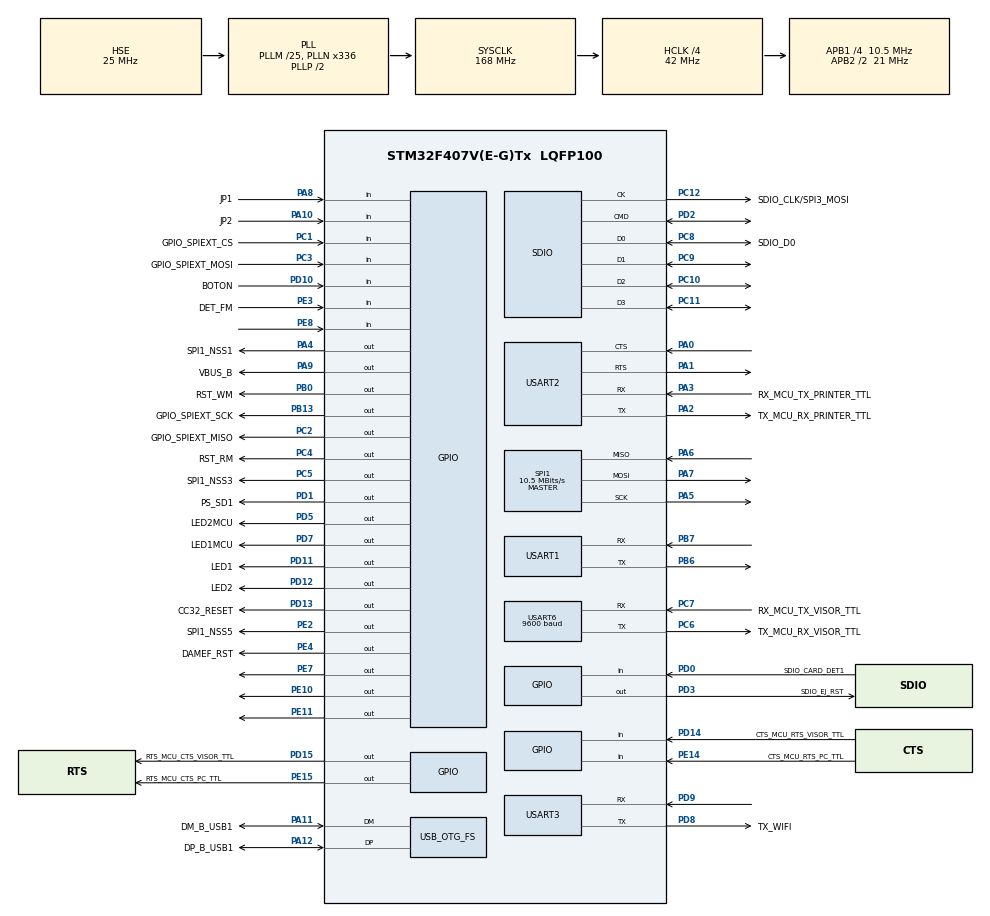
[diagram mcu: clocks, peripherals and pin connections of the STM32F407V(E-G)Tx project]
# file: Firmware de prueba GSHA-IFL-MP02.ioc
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Dma.Request0=SDIO_RX
Dma.Request1=SDIO_TX
Dma.SDIO_RX.0.Direction=DMA_PERIPH_TO_MEMORY
Dma.SDIO_RX.0.FIFOMode=DMA_FIFOMODE_ENABLE
Dma.SDIO_RX.0.FIFOThreshold=DMA_FIFO_THRESHOLD_FULL
Dma.SDIO_RX.0.Instance=DMA2_Stream3
Dma.SDIO_RX.0.MemBurst=DMA_MBURST_INC4
Dma.SDIO_RX.0.MemDataAlignment=DMA_MDATAALIGN_WORD
Dma.SDIO_RX.0.MemInc=DMA_MINC_ENABLE
Dma.SDIO_RX.0.Mode=DMA_PFCTRL
Dma.SDIO_RX.0.PeriphBurst=DMA_PBURST_INC4
Dma.SDIO_RX.0.PeriphDataAlignment=DMA_PDATAALIGN_WORD
Dma.SDIO_RX.0.PeriphInc=DMA_PINC_DISABLE
Dma.SDIO_RX.0.Priority=DMA_PRIORITY_LOW
Dma.SDIO_TX.1.Direction=DMA_MEMORY_TO_PERIPH
Dma.SDIO_TX.1.FIFOMode=DMA_FIFOMODE_ENABLE
Dma.SDIO_TX.1.FIFOThreshold=DMA_FIFO_THRESHOLD_FULL
Dma.SDIO_TX.1.Instance=DMA2_Stream6
Dma.SDIO_TX.1.MemBurst=DMA_MBURST_INC4
Dma.SDIO_TX.1.MemDataAlignment=DMA_MDATAALIGN_WORD
Dma.SDIO_TX.1.MemInc=DMA_MINC_ENABLE
Dma.SDIO_TX.1.Mode=DMA_PFCTRL
Dma.SDIO_TX.1.PeriphBurst=DMA_PBURST_INC4
Dma.SDIO_TX.1.PeriphDataAlignment=DMA_PDATAALIGN_WORD
Dma.SDIO_TX.1.PeriphInc=DMA_PINC_DISABLE
Dma.SDIO_TX.1.Priority=DMA_PRIORITY_LOW
FATFS.BSP.number=1
FATFS._MAX_SS=4096
FATFS0.BSP.STBoard=false
FATFS0.BSP.api=Unknown
FATFS0.BSP.i2caddr=0
FATFS0.BSP.instance=PD0
FATFS0.BSP.ip=GPIO
FATFS0.BSP.mode=Input
FATFS0.BSP.name=Detect_SDIO
FATFS0.BSP.solution=PD0
Mcu.Family=STM32F4
Mcu.Name=STM32F407V(E-G)Tx
Mcu.Package=LQFP100
NVIC.DMA2_Stream3_IRQn=true\:0\:0\:false\:false\:true\:true\:true
NVIC.DMA2_Stream6_IRQn=true\:0\:0\:false\:false\:true\:true\:true
NVIC.OTG_FS_IRQn=true\:0\:0\:false\:false\:true\:true\:true
NVIC.PriorityGroup=NVIC_PRIORITYGROUP_4
NVIC.SDIO_IRQn=true\:0\:0\:false\:false\:true\:true\:true
NVIC.USART2_IRQn=true\:0\:0\:false\:false\:true\:true\:true
NVIC.USART3_IRQn=true\:0\:0\:false\:false\:true\:true\:true
NVIC.USART6_IRQn=true\:0\:0\:false\:false\:true\:true\:true
PA0-WKUP.Mode=CTS_RTS
PA0-WKUP.Signal=USART2_CTS
PA1.Mode=CTS_RTS
PA1.Signal=USART2_RTS
PA10.GPIO_Label=JP2
PA10.Signal=GPIO_Input
PA11.GPIO_Label=DM_B_USB1
PA11.Mode=Device_Only
PA11.Signal=USB_OTG_FS_DM
PA12.GPIO_Label=DP_B_USB1
PA12.Mode=Device_Only
PA12.Signal=USB_OTG_FS_DP
PA13.Mode=JTAG_5_pins
PA13.Signal=SYS_JTMS-SWDIO
PA14.Mode=JTAG_5_pins
PA14.Signal=SYS_JTCK-SWCLK
PA15.Mode=JTAG_5_pins
PA15.Signal=SYS_JTDI
PA2.GPIO_Label=TX_MCU_RX_PRINTER_TTL
PA2.Mode=Asynchronous
PA2.Signal=USART2_TX
PA3.GPIO_Label=RX_MCU_TX_PRINTER_TTL
PA3.Mode=Asynchronous
PA3.Signal=USART2_RX
PA4.GPIO_Label=SPI1_NSS1
PA4.Signal=GPIO_Output
PA5.Mode=Full_Duplex_Master
PA5.Signal=SPI1_SCK
PA6.Mode=Full_Duplex_Master
PA6.Signal=SPI1_MISO
PA7.Mode=Full_Duplex_Master
PA7.Signal=SPI1_MOSI
PA8.GPIO_Label=JP1
PA8.Signal=GPIO_Input
PA9.GPIO_Label=VBUS_B
PA9.GPIO_Speed=GPIO_SPEED_FREQ_MEDIUM
PA9.PinState=GPIO_PIN_SET
PA9.Signal=GPIO_Output
PB0.GPIO_Label=RST_WM
PB0.Signal=GPIO_Output
PB13.GPIO_Label=GPIO_SPIEXT_SCK
PB13.Signal=GPIO_Output
PB3.Mode=JTAG_5_pins
PB3.Signal=SYS_JTDO-SWO
PB4.Mode=JTAG_5_pins
PB4.Signal=SYS_JTRST
PB6.Mode=Asynchronous
PB6.Signal=USART1_TX
PB7.Mode=Asynchronous
PB7.Signal=USART1_RX
PC1.GPIO_Label=GPIO_SPIEXT_CS
PC1.Signal=GPIO_Input
PC10.Mode=SD_4_bits_Wide_bus
PC10.Signal=SDIO_D2
PC11.Mode=SD_4_bits_Wide_bus
PC11.Signal=SDIO_D3
PC12.GPIO_Label=SDIO_CLK/SPI3_MOSI
PC12.GPIO_Mode=GPIO_MODE_AF_PP
PC12.GPIO_PuPd=GPIO_NOPULL
PC12.GPIO_Speed_High_Default=GPIO_SPEED_FREQ_VERY_HIGH
PC12.Mode=SD_4_bits_Wide_bus
PC12.Signal=SDIO_CK
PC14-OSC32_IN.Mode=LSE-External-Oscillator
PC14-OSC32_IN.Signal=RCC_OSC32_IN
PC15-OSC32_OUT.Mode=LSE-External-Oscillator
PC15-OSC32_OUT.Signal=RCC_OSC32_OUT
PC2.GPIO_Label=GPIO_SPIEXT_MISO
PC2.Signal=GPIO_Output
PC3.GPIO_Label=GPIO_SPIEXT_MOSI
PC3.Signal=GPIO_Input
PC4.GPIO_Label=RST_RM
PC4.GPIO_ModeDefaultOutputPP=GPIO_MODE_OUTPUT_PP
PC4.GPIO_PuPd=GPIO_NOPULL
PC4.GPIO_Speed=GPIO_SPEED_FREQ_VERY_HIGH
PC4.PinState=GPIO_PIN_SET
PC4.Signal=GPIO_Output
PC5.GPIO_Label=SPI1_NSS3
PC5.GPIO_ModeDefaultOutputPP=GPIO_MODE_OUTPUT_PP
PC5.GPIO_PuPd=GPIO_NOPULL
PC5.GPIO_Speed=GPIO_SPEED_FREQ_VERY_HIGH
PC5.PinState=GPIO_PIN_SET
PC5.Signal=GPIO_Output
PC6.GPIO_Label=TX_MCU_RX_VISOR_TTL
PC6.Mode=Asynchronous
PC6.Signal=USART6_TX
PC7.GPIO_Label=RX_MCU_TX_VISOR_TTL
PC7.Mode=Asynchronous
PC7.Signal=USART6_RX
PC8.GPIO_Label=SDIO_D0
PC8.GPIO_Mode=GPIO_MODE_AF_PP
PC8.GPIO_PuPd=GPIO_PULLUP
PC8.GPIO_Speed_High_Default=GPIO_SPEED_FREQ_VERY_HIGH
PC8.Mode=SD_4_bits_Wide_bus
PC8.Signal=SDIO_D0
PC9.Mode=SD_4_bits_Wide_bus
PC9.Signal=SDIO_D1
PD0.GPIO_Label=SDIO_CARD_DET1
PD0.Signal=GPIO_Input
PD1.GPIO_Label=PS_SD1
PD1.GPIO_Speed=GPIO_SPEED_FREQ_MEDIUM
PD1.Signal=GPIO_Output
PD10.GPIO_Label=BOTON
PD10.GPIO_PuPd=GPIO_PULLUP
PD10.Signal=GPIO_Input
PD11.GPIO_Label=LED1
PD11.GPIO_ModeDefaultOutputPP=GPIO_MODE_OUTPUT_PP
PD11.GPIO_PuPd=GPIO_NOPULL
PD11.GPIO_Speed=GPIO_SPEED_FREQ_HIGH
PD11.PinState=GPIO_PIN_RESET
PD11.Signal=GPIO_Output
PD12.GPIO_Label=LED2
PD12.GPIO_ModeDefaultOutputPP=GPIO_MODE_OUTPUT_PP
PD12.GPIO_PuPd=GPIO_NOPULL
PD12.GPIO_Speed=GPIO_SPEED_FREQ_HIGH
PD12.PinState=GPIO_PIN_RESET
PD12.Signal=GPIO_Output
PD13.GPIO_Label=CC32_RESET
PD13.Signal=GPIO_Output
PD14.GPIO_Label=CTS_MCU_RTS_VISOR_TTL
PD14.Signal=GPIO_Input
PD15.GPIO_Label=RTS_MCU_CTS_VISOR_TTL
PD15.Signal=GPIO_Output
PD2.GPIO_Mode=GPIO_MODE_AF_PP
PD2.GPIO_PuPd=GPIO_PULLUP
PD2.GPIO_Speed_High_Default=GPIO_SPEED_FREQ_VERY_HIGH
PD2.Mode=SD_4_bits_Wide_bus
PD2.Signal=SDIO_CMD
PD3.GPIO_Label=SDIO_EJ_RST
PD3.Signal=GPIO_Output
PD5.GPIO_Label=LED2MCU
PD5.Signal=GPIO_Output
PD7.GPIO_Label=LED1MCU
PD7.Signal=GPIO_Output
PD8.GPIO_Label=TX_WIFI
PD8.Mode=Asynchronous
PD8.Signal=USART3_TX
PD9.Mode=Asynchronous
PD9.Signal=USART3_RX
PE10.Signal=GPIO_Output
PE11.Signal=GPIO_Output
PE14.GPIO_Label=CTS_MCU_RTS_PC_TTL
PE14.Signal=GPIO_Input
PE15.GPIO_Label=RTS_MCU_CTS_PC_TTL
PE15.Signal=GPIO_Output
PE2.GPIO_Label=SPI1_NSS5
PE2.GPIO_Speed=GPIO_SPEED_FREQ_VERY_HIGH
PE2.PinState=GPIO_PIN_SET
PE2.Signal=GPIO_Output
PE3.GPIO_Label=DET_FM
PE3.Signal=GPIO_Input
PE4.GPIO_Label=DAMEF_RST
PE4.GPIO_Speed=GPIO_SPEED_FREQ_VERY_HIGH
PE4.PinState=GPIO_PIN_SET
PE4.Signal=GPIO_Output
PE7.Signal=GPIO_Output
PE8.Signal=GPIO_Input
PH0-OSC_IN.Mode=HSE-External-Oscillator
PH0-OSC_IN.Signal=RCC_OSC_IN
PH1-OSC_OUT.Mode=HSE-External-Oscillator
PH1-OSC_OUT.Signal=RCC_OSC_OUT
ProjectManager.HeapSize=0x2000
ProjectManager.StackSize=0x4000
ProjectManager.TargetToolchain=MDK-ARM V5
RCC.48MHZClocksFreq_Value=48000000
RCC.AHBCLKDivider=RCC_SYSCLK_DIV4
RCC.AHBFreq_Value=42000000
RCC.APB1CLKDivider=RCC_HCLK_DIV4
RCC.APB1Freq_Value=10500000
RCC.APB1TimFreq_Value=21000000
RCC.APB2CLKDivider=RCC_HCLK_DIV2
RCC.APB2Freq_Value=21000000
RCC.APB2TimFreq_Value=42000000
RCC.CortexFreq_Value=42000000
RCC.HCLKFreq_Value=42000000
RCC.HSE_VALUE=25000000
RCC.HSI_VALUE=16000000
RCC.PLLM=25
RCC.PLLN=336
RCC.PLLQ=7
RCC.RCC_RTC_Clock_Source=RCC_RTCCLKSOURCE_LSE
RCC.RCC_RTC_Clock_SourceVirtual=RCC_RTCCLKSOURCE_LSE
RCC.SYSCLKFreq_VALUE=168000000
RCC.SYSCLKSource=RCC_SYSCLKSOURCE_PLLCLK
RCC.VCOOutputFreq_Value=336000000
RTC.Alarm=RTC_ALARM_A
SDIO.ClockDiv=3
SDIO.WideMode=SDIO_BUS_WIDE_4B
SPI1.CalculateBaudRate=10.5 MBits/s
SPI1.Direction=SPI_DIRECTION_2LINES
SPI1.Mode=SPI_MODE_MASTER
SPI1.VirtualType=VM_MASTER
USART1.VirtualMode=VM_ASYNC
USART2.VirtualMode=VM_ASYNC
USART3.VirtualMode=VM_ASYNC
USART6.BaudRate=9600
USART6.VirtualMode=VM_ASYNC
USB_DEVICE.CLASS_NAME-CDC_FS=CDC
USB_DEVICE.CLASS_NAME_FS=CDC
USB_DEVICE.MANUFACTURER_STRING-CDC_FS=The Factory HKA
USB_DEVICE.PRODUCT_STRING_CDC_FS=Tarjeta de comunicaicon HKA
USB_DEVICE.USBD_HandleTypeDef-CDC_FS=hUsbDeviceFS
USB_DEVICE.VirtualMode-CDC_FS=Cdc
USB_DEVICE.VirtualModeFS=Cdc_FS
USB_OTG_FS.VirtualMode=Device_Only
VP_FATFS_VS_SDIO.Mode=SDIO
VP_RTC_VS_RTC_Activate.Mode=RTC_Enabled
VP_RTC_VS_RTC_Alarm_A_Intern.Mode=Alarm A
VP_RTC_VS_RTC_Calendar.Mode=RTC_Calendar
VP_USB_DEVICE_VS_USB_DEVICE_CDC_FS.Mode=CDC_FS
board=Firmware de prueba GSHA-IFL-MP02

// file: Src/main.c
/* USER CODE BEGIN Header */
/**
  ******************************************************************************
  * @file           : main.c
  * @brief          : Main program body
  ******************************************************************************
  * @attention
  *
  * <h2><center>&copy; Copyright (c) 2021 STMicroelectronics.
  * All rights reserved.</center></h2>
  *
  * This software component is licensed by ST under Ultimate Liberty license
  * SLA0044, the "License"; You may not use this file except in compliance with
  * the License. You may obtain a copy of the License at:
  *                             www.st.com/SLA0044
  *
  ******************************************************************************
  */
/* USER CODE END Header */
#include "main.h"
#include "fatfs.h"
#include "usb_device.h"

/* USER CODE BEGIN Includes */
//#include "UartRingbuffer.h"
//#include "file_handling.h"
#include "selftest.h"
/* USER CODE END Includes */

RTC_HandleTypeDef hrtc;

SD_HandleTypeDef hsd;
DMA_HandleTypeDef hdma_sdio_rx;
DMA_HandleTypeDef hdma_sdio_tx;

SPI_HandleTypeDef hspi1;

UART_HandleTypeDef huart1;
UART_HandleTypeDef huart2;
UART_HandleTypeDef huart3;
UART_HandleTypeDef huart6;

void SystemClock_Config(void);
static void MX_GPIO_Init(void);
static void MX_DMA_Init(void);
static void MX_RTC_Init(void);
static void MX_SDIO_SD_Init(void);
static void MX_USART1_UART_Init(void);
static void MX_USART2_UART_Init(void);
static void MX_USART6_UART_Init(void);
static void MX_USART3_UART_Init(void);
static void MX_SPI1_Init(void);

int main(void)
{

  /* MCU Configuration--------------------------------------------------------*/

  /* Reset of all peripherals, Initializes the Flash interface and the Systick. */
  HAL_Init();

  /* Configure the system clock */
  SystemClock_Config();

  /* Initialize all configured peripherals */
  MX_GPIO_Init();
  MX_DMA_Init();
  MX_RTC_Init();
  MX_SDIO_SD_Init();
  MX_USART1_UART_Init();
  MX_USART2_UART_Init();
  MX_USART6_UART_Init();
  MX_FATFS_Init();
  MX_USB_DEVICE_Init();
  MX_USART3_UART_Init();
  MX_SPI1_Init();
  /* USER CODE BEGIN 2 */
  int loop=3;
  /* USER CODE END 2 */

  /* Infinite loop */
  /* USER CODE BEGIN WHILE */
  while (1)
  {
		HAL_Delay(2000);
    //Mensaje inicial

		ALLISON_init();

		//Ejecucion del selftest del STM32

		selftest();

		while(loop){
		led_ok();
			loop--;
		}

    //Prueba del CC3220

		CC32_Selftest();

		//while(1){}

}	/* USER CODE END WHILE */

}
void SystemClock_Config(void)
{
  RCC_OscInitTypeDef RCC_OscInitStruct = {0};
  RCC_ClkInitTypeDef RCC_ClkInitStruct = {0};
  RCC_PeriphCLKInitTypeDef PeriphClkInitStruct = {0};

  /** Configure the main internal regulator output voltage
  */
  __HAL_RCC_PWR_CLK_ENABLE();
  __HAL_PWR_VOLTAGESCALING_CONFIG(PWR_REGULATOR_VOLTAGE_SCALE1);
  /** Initializes the RCC Oscillators according to the specified parameters
  * in the RCC_OscInitTypeDef structure.
  */
  RCC_OscInitStruct.OscillatorType = RCC_OSCILLATORTYPE_HSE|RCC_OSCILLATORTYPE_LSE;
  RCC_OscInitStruct.HSEState = RCC_HSE_ON;
  RCC_OscInitStruct.LSEState = RCC_LSE_ON;
  RCC_OscInitStruct.PLL.PLLState = RCC_PLL_ON;
  RCC_OscInitStruct.PLL.PLLSource = RCC_PLLSOURCE_HSE;
  RCC_OscInitStruct.PLL.PLLM = 25;
  RCC_OscInitStruct.PLL.PLLN = 336;
  RCC_OscInitStruct.PLL.PLLP = RCC_PLLP_DIV2;
  RCC_OscInitStruct.PLL.PLLQ = 7;
  if (HAL_RCC_OscConfig(&RCC_OscInitStruct) != HAL_OK)
  {
    Error_Handler();
  }
  /** Initializes the CPU, AHB and APB buses clocks
  */
  RCC_ClkInitStruct.ClockType = RCC_CLOCKTYPE_HCLK|RCC_CLOCKTYPE_SYSCLK
                              |RCC_CLOCKTYPE_PCLK1|RCC_CLOCKTYPE_PCLK2;
  RCC_ClkInitStruct.SYSCLKSource = RCC_SYSCLKSOURCE_PLLCLK;
  RCC_ClkInitStruct.AHBCLKDivider = RCC_SYSCLK_DIV4;
  RCC_ClkInitStruct.APB1CLKDivider = RCC_HCLK_DIV4;
  RCC_ClkInitStruct.APB2CLKDivider = RCC_HCLK_DIV2;

  if (HAL_RCC_ClockConfig(&RCC_ClkInitStruct, FLASH_LATENCY_1) != HAL_OK)
  {
    Error_Handler();
  }
  PeriphClkInitStruct.PeriphClockSelection = RCC_PERIPHCLK_RTC;
  PeriphClkInitStruct.RTCClockSelection = RCC_RTCCLKSOURCE_LSE;
  if (HAL_RCCEx_PeriphCLKConfig(&PeriphClkInitStruct) != HAL_OK)
  {
    Error_Handler();
  }
}

static void MX_RTC_Init(void)
{

  RTC_TimeTypeDef sTime = {0};
  RTC_DateTypeDef sDate = {0};
  RTC_AlarmTypeDef sAlarm = {0};

  /** Initialize RTC Only
  */
  hrtc.Instance = RTC;
  hrtc.Init.HourFormat = RTC_HOURFORMAT_24;
  hrtc.Init.AsynchPrediv = 127;
  hrtc.Init.SynchPrediv = 255;
  hrtc.Init.OutPut = RTC_OUTPUT_DISABLE;
  hrtc.Init.OutPutPolarity = RTC_OUTPUT_POLARITY_HIGH;
  hrtc.Init.OutPutType = RTC_OUTPUT_TYPE_OPENDRAIN;
  if (HAL_RTC_Init(&hrtc) != HAL_OK)
  {
    Error_Handler();
  }

  /** Initialize RTC and set the Time and Date
  */
  sTime.Hours = 0x0;
  sTime.Minutes = 0x0;
  sTime.Seconds = 0x0;
  sTime.DayLightSaving = RTC_DAYLIGHTSAVING_NONE;
  sTime.StoreOperation = RTC_STOREOPERATION_RESET;
  if (HAL_RTC_SetTime(&hrtc, &sTime, RTC_FORMAT_BCD) != HAL_OK)
  {
    Error_Handler();
  }
  sDate.WeekDay = RTC_WEEKDAY_MONDAY;
  sDate.Month = RTC_MONTH_JANUARY;
  sDate.Date = 0x1;
  sDate.Year = 0x0;

  if (HAL_RTC_SetDate(&hrtc, &sDate, RTC_FORMAT_BCD) != HAL_OK)
  {
    Error_Handler();
  }
  /** Enable the Alarm A
  */
  sAlarm.AlarmTime.Hours = 0x0;
  sAlarm.AlarmTime.Minutes = 0x0;
  sAlarm.AlarmTime.Seconds = 0x0;
  sAlarm.AlarmTime.SubSeconds = 0x0;
  sAlarm.AlarmTime.DayLightSaving = RTC_DAYLIGHTSAVING_NONE;
  sAlarm.AlarmTime.StoreOperation = RTC_STOREOPERATION_RESET;
  sAlarm.AlarmMask = RTC_ALARMMASK_NONE;
  sAlarm.AlarmSubSecondMask = RTC_ALARMSUBSECONDMASK_ALL;
  sAlarm.AlarmDateWeekDaySel = RTC_ALARMDATEWEEKDAYSEL_DATE;
  sAlarm.AlarmDateWeekDay = 0x1;
  sAlarm.Alarm = RTC_ALARM_A;
  if (HAL_RTC_SetAlarm(&hrtc, &sAlarm, RTC_FORMAT_BCD) != HAL_OK)
  {
    Error_Handler();
  }

}

static void MX_SDIO_SD_Init(void)
{

  hsd.Instance = SDIO;
  hsd.Init.ClockEdge = SDIO_CLOCK_EDGE_RISING;
  hsd.Init.ClockBypass = SDIO_CLOCK_BYPASS_DISABLE;
  hsd.Init.ClockPowerSave = SDIO_CLOCK_POWER_SAVE_DISABLE;
  hsd.Init.BusWide = SDIO_BUS_WIDE_1B;
  hsd.Init.HardwareFlowControl = SDIO_HARDWARE_FLOW_CONTROL_DISABLE;
  hsd.Init.ClockDiv = 3;

}

static void MX_SPI1_Init(void)
{

  /* SPI1 parameter configuration*/
  hspi1.Instance = SPI1;
  hspi1.Init.Mode = SPI_MODE_MASTER;
  hspi1.Init.Direction = SPI_DIRECTION_2LINES;
  hspi1.Init.DataSize = SPI_DATASIZE_8BIT;
  hspi1.Init.CLKPolarity = SPI_POLARITY_LOW;
  hspi1.Init.CLKPhase = SPI_PHASE_1EDGE;
  hspi1.Init.NSS = SPI_NSS_SOFT;
  hspi1.Init.BaudRatePrescaler = SPI_BAUDRATEPRESCALER_2;
  hspi1.Init.FirstBit = SPI_FIRSTBIT_MSB;
  hspi1.Init.TIMode = SPI_TIMODE_DISABLE;
  hspi1.Init.CRCCalculation = SPI_CRCCALCULATION_DISABLE;
  hspi1.Init.CRCPolynomial = 10;
  if (HAL_SPI_Init(&hspi1) != HAL_OK)
  {
    Error_Handler();
  }

}

static void MX_USART1_UART_Init(void)
{

  huart1.Instance = USART1;
  huart1.Init.BaudRate = 115200;
  huart1.Init.WordLength = UART_WORDLENGTH_8B;
  huart1.Init.StopBits = UART_STOPBITS_1;
  huart1.Init.Parity = UART_PARITY_NONE;
  huart1.Init.Mode = UART_MODE_TX_RX;
  huart1.Init.HwFlowCtl = UART_HWCONTROL_NONE;
  huart1.Init.OverSampling = UART_OVERSAMPLING_16;
  if (HAL_UART_Init(&huart1) != HAL_OK)
  {
    Error_Handler();
  }

}

static void MX_USART2_UART_Init(void)
{

  huart2.Instance = USART2;
  huart2.Init.BaudRate = 115200;
  huart2.Init.WordLength = UART_WORDLENGTH_8B;
  huart2.Init.StopBits = UART_STOPBITS_1;
  huart2.Init.Parity = UART_PARITY_NONE;
  huart2.Init.Mode = UART_MODE_TX_RX;
  huart2.Init.HwFlowCtl = UART_HWCONTROL_RTS_CTS;
  huart2.Init.OverSampling = UART_OVERSAMPLING_16;
  if (HAL_UART_Init(&huart2) != HAL_OK)
  {
    Error_Handler();
  }

}

static void MX_USART3_UART_Init(void)
{

  huart3.Instance = USART3;
  huart3.Init.BaudRate = 115200;
  huart3.Init.WordLength = UART_WORDLENGTH_8B;
  huart3.Init.StopBits = UART_STOPBITS_1;
  huart3.Init.Parity = UART_PARITY_NONE;
  huart3.Init.Mode = UART_MODE_TX_RX;
  huart3.Init.HwFlowCtl = UART_HWCONTROL_NONE;
  huart3.Init.OverSampling = UART_OVERSAMPLING_16;
  if (HAL_UART_Init(&huart3) != HAL_OK)
  {
    Error_Handler();
  }

}

static void MX_USART6_UART_Init(void)
{

  huart6.Instance = USART6;
  huart6.Init.BaudRate = 9600;
  huart6.Init.WordLength = UART_WORDLENGTH_8B;
  huart6.Init.StopBits = UART_STOPBITS_1;
  huart6.Init.Parity = UART_PARITY_NONE;
  huart6.Init.Mode = UART_MODE_TX_RX;
  huart6.Init.HwFlowCtl = UART_HWCONTROL_NONE;
  huart6.Init.OverSampling = UART_OVERSAMPLING_16;
  if (HAL_UART_Init(&huart6) != HAL_OK)
  {
    Error_Handler();
  }

}

static void MX_DMA_Init(void)
{

  /* DMA controller clock enable */
  __HAL_RCC_DMA2_CLK_ENABLE();

  /* DMA interrupt init */
  /* DMA2_Stream3_IRQn interrupt configuration */
  HAL_NVIC_SetPriority(DMA2_Stream3_IRQn, 0, 0);
  HAL_NVIC_EnableIRQ(DMA2_Stream3_IRQn);
  /* DMA2_Stream6_IRQn interrupt configuration */
  HAL_NVIC_SetPriority(DMA2_Stream6_IRQn, 0, 0);
  HAL_NVIC_EnableIRQ(DMA2_Stream6_IRQn);

}

static void MX_GPIO_Init(void)
{
  GPIO_InitTypeDef GPIO_InitStruct = {0};

  /* GPIO Ports Clock Enable */
  __HAL_RCC_GPIOE_CLK_ENABLE();
  __HAL_RCC_GPIOC_CLK_ENABLE();
  __HAL_RCC_GPIOH_CLK_ENABLE();
  __HAL_RCC_GPIOA_CLK_ENABLE();
  __HAL_RCC_GPIOB_CLK_ENABLE();
  __HAL_RCC_GPIOD_CLK_ENABLE();

  /*Configure GPIO pin Output Level */
  HAL_GPIO_WritePin(GPIOE, SPI1_NSS5_Pin|DAMEF_RST_Pin, GPIO_PIN_SET);

  /*Configure GPIO pin Output Level */
  HAL_GPIO_WritePin(GPIO_SPIEXT_MISO_GPIO_Port, GPIO_SPIEXT_MISO_Pin, GPIO_PIN_RESET);

  /*Configure GPIO pin Output Level */
  HAL_GPIO_WritePin(SPI1_NSS1_GPIO_Port, SPI1_NSS1_Pin, GPIO_PIN_RESET);

  /*Configure GPIO pin Output Level */
  HAL_GPIO_WritePin(GPIOC, RST_RM_Pin|SPI1_NSS3_Pin, GPIO_PIN_SET);

  /*Configure GPIO pin Output Level */
  HAL_GPIO_WritePin(GPIOB, RST_WM_Pin|GPIO_SPIEXT_SCK_Pin, GPIO_PIN_RESET);

  /*Configure GPIO pin Output Level */
  HAL_GPIO_WritePin(GPIOE, GPIO_PIN_7|GPIO_PIN_10|GPIO_PIN_11|RTS_MCU_CTS_PC_TTL_Pin, GPIO_PIN_RESET);

  /*Configure GPIO pin Output Level */
  HAL_GPIO_WritePin(GPIOD, LED1_Pin|LED2_Pin|CC32_RESET_Pin|RTS_MCU_CTS_VISOR_TTL_Pin
                          |PS_SD1_Pin|SDIO_EJ_RST_Pin|LED2MCU_Pin|LED1MCU_Pin, GPIO_PIN_RESET);

  /*Configure GPIO pin Output Level */
  HAL_GPIO_WritePin(VBUS_B_GPIO_Port, VBUS_B_Pin, GPIO_PIN_SET);

  /*Configure GPIO pins : SPI1_NSS5_Pin DAMEF_RST_Pin */
  GPIO_InitStruct.Pin = SPI1_NSS5_Pin|DAMEF_RST_Pin;
  GPIO_InitStruct.Mode = GPIO_MODE_OUTPUT_PP;
  GPIO_InitStruct.Pull = GPIO_NOPULL;
  GPIO_InitStruct.Speed = GPIO_SPEED_FREQ_VERY_HIGH;
  HAL_GPIO_Init(GPIOE, &GPIO_InitStruct);

  /*Configure GPIO pins : DET_FM_Pin PE8 CTS_MCU_RTS_PC_TTL_Pin */
  GPIO_InitStruct.Pin = DET_FM_Pin|GPIO_PIN_8|CTS_MCU_RTS_PC_TTL_Pin;
  GPIO_InitStruct.Mode = GPIO_MODE_INPUT;
  GPIO_InitStruct.Pull = GPIO_NOPULL;
  HAL_GPIO_Init(GPIOE, &GPIO_InitStruct);

  /*Configure GPIO pins : GPIO_SPIEXT_CS_Pin GPIO_SPIEXT_MOSI_Pin */
  GPIO_InitStruct.Pin = GPIO_SPIEXT_CS_Pin|GPIO_SPIEXT_MOSI_Pin;
  GPIO_InitStruct.Mode = GPIO_MODE_INPUT;
  GPIO_InitStruct.Pull = GPIO_NOPULL;
  HAL_GPIO_Init(GPIOC, &GPIO_InitStruct);

  /*Configure GPIO pin : GPIO_SPIEXT_MISO_Pin */
  GPIO_InitStruct.Pin = GPIO_SPIEXT_MISO_Pin;
  GPIO_InitStruct.Mode = GPIO_MODE_OUTPUT_PP;
  GPIO_InitStruct.Pull = GPIO_NOPULL;
  GPIO_InitStruct.Speed = GPIO_SPEED_FREQ_LOW;
  HAL_GPIO_Init(GPIO_SPIEXT_MISO_GPIO_Port, &GPIO_InitStruct);

  /*Configure GPIO pin : SPI1_NSS1_Pin */
  GPIO_InitStruct.Pin = SPI1_NSS1_Pin;
  GPIO_InitStruct.Mode = GPIO_MODE_OUTPUT_PP;
  GPIO_InitStruct.Pull = GPIO_NOPULL;
  GPIO_InitStruct.Speed = GPIO_SPEED_FREQ_LOW;
  HAL_GPIO_Init(SPI1_NSS1_GPIO_Port, &GPIO_InitStruct);

  /*Configure GPIO pins : RST_RM_Pin SPI1_NSS3_Pin */
  GPIO_InitStruct.Pin = RST_RM_Pin|SPI1_NSS3_Pin;
  GPIO_InitStruct.Mode = GPIO_MODE_OUTPUT_PP;
  GPIO_InitStruct.Pull = GPIO_NOPULL;
  GPIO_InitStruct.Speed = GPIO_SPEED_FREQ_VERY_HIGH;
  HAL_GPIO_Init(GPIOC, &GPIO_InitStruct);

  /*Configure GPIO pins : RST_WM_Pin GPIO_SPIEXT_SCK_Pin */
  GPIO_InitStruct.Pin = RST_WM_Pin|GPIO_SPIEXT_SCK_Pin;
  GPIO_InitStruct.Mode = GPIO_MODE_OUTPUT_PP;
  GPIO_InitStruct.Pull = GPIO_NOPULL;
  GPIO_InitStruct.Speed = GPIO_SPEED_FREQ_LOW;
  HAL_GPIO_Init(GPIOB, &GPIO_InitStruct);

  /*Configure GPIO pins : PE7 PE10 PE11 RTS_MCU_CTS_PC_TTL_Pin */
  GPIO_InitStruct.Pin = GPIO_PIN_7|GPIO_PIN_10|GPIO_PIN_11|RTS_MCU_CTS_PC_TTL_Pin;
  GPIO_InitStruct.Mode = GPIO_MODE_OUTPUT_PP;
  GPIO_InitStruct.Pull = GPIO_NOPULL;
  GPIO_InitStruct.Speed = GPIO_SPEED_FREQ_LOW;
  HAL_GPIO_Init(GPIOE, &GPIO_InitStruct);

  /*Configure GPIO pin : BOTON_Pin */
  GPIO_InitStruct.Pin = BOTON_Pin;
  GPIO_InitStruct.Mode = GPIO_MODE_INPUT;
  GPIO_InitStruct.Pull = GPIO_PULLUP;
  HAL_GPIO_Init(BOTON_GPIO_Port, &GPIO_InitStruct);

  /*Configure GPIO pins : LED1_Pin LED2_Pin */
  GPIO_InitStruct.Pin = LED1_Pin|LED2_Pin;
  GPIO_InitStruct.Mode = GPIO_MODE_OUTPUT_PP;
  GPIO_InitStruct.Pull = GPIO_NOPULL;
  GPIO_InitStruct.Speed = GPIO_SPEED_FREQ_HIGH;
  HAL_GPIO_Init(GPIOD, &GPIO_InitStruct);

  /*Configure GPIO pins : CC32_RESET_Pin RTS_MCU_CTS_VISOR_TTL_Pin SDIO_EJ_RST_Pin LED2MCU_Pin
                           LED1MCU_Pin */
  GPIO_InitStruct.Pin = CC32_RESET_Pin|RTS_MCU_CTS_VISOR_TTL_Pin|SDIO_EJ_RST_Pin|LED2MCU_Pin
                          |LED1MCU_Pin;
  GPIO_InitStruct.Mode = GPIO_MODE_OUTPUT_PP;
  GPIO_InitStruct.Pull = GPIO_NOPULL;
  GPIO_InitStruct.Speed = GPIO_SPEED_FREQ_LOW;
  HAL_GPIO_Init(GPIOD, &GPIO_InitStruct);

  /*Configure GPIO pins : CTS_MCU_RTS_VISOR_TTL_Pin SDIO_CARD_DET1_Pin */
  GPIO_InitStruct.Pin = CTS_MCU_RTS_VISOR_TTL_Pin|SDIO_CARD_DET1_Pin;
  GPIO_InitStruct.Mode = GPIO_MODE_INPUT;
  GPIO_InitStruct.Pull = GPIO_NOPULL;
  HAL_GPIO_Init(GPIOD, &GPIO_InitStruct);

  /*Configure GPIO pins : JP1_Pin JP2_Pin */
  GPIO_InitStruct.Pin = JP1_Pin|JP2_Pin;
  GPIO_InitStruct.Mode = GPIO_MODE_INPUT;
  GPIO_InitStruct.Pull = GPIO_NOPULL;
  HAL_GPIO_Init(GPIOA, &GPIO_InitStruct);

  /*Configure GPIO pin : VBUS_B_Pin */
  GPIO_InitStruct.Pin = VBUS_B_Pin;
  GPIO_InitStruct.Mode = GPIO_MODE_OUTPUT_PP;
  GPIO_InitStruct.Pull = GPIO_NOPULL;
  GPIO_InitStruct.Speed = GPIO_SPEED_FREQ_MEDIUM;
  HAL_GPIO_Init(VBUS_B_GPIO_Port, &GPIO_InitStruct);

  /*Configure GPIO pin : PS_SD1_Pin */
  GPIO_InitStruct.Pin = PS_SD1_Pin;
  GPIO_InitStruct.Mode = GPIO_MODE_OUTPUT_PP;
  GPIO_InitStruct.Pull = GPIO_NOPULL;
  GPIO_InitStruct.Speed = GPIO_SPEED_FREQ_MEDIUM;
  HAL_GPIO_Init(PS_SD1_GPIO_Port, &GPIO_InitStruct);

}

void Error_Handler(void)
{
  __disable_irq();
  while (1)
  {
  }
}

/************************ (C) COPYRIGHT STMicroelectronics *****END OF FILE****/
